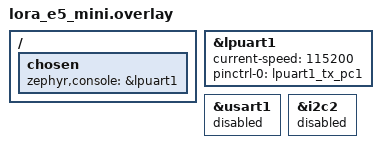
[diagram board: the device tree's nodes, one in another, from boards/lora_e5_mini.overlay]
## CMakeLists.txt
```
cmake_minimum_required(VERSION 3.20.0)
find_package(Zephyr REQUIRED HINTS $ENV{ZEPHYR_BASE})
project(loralink)

target_sources(app PRIVATE 
    src/main.c
    src/ping.c
    src/pong.c
)

if(DEFINED FW_VERSION)
    add_compile_definitions(FW_VERSION="${FW_VERSION}")
endif()
```

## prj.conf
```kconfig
# LoRa driver subsystem
CONFIG_LORA=y
CONFIG_LORA_MODULE_BACKEND_NATIVE=y

CONFIG_GPIO=y

# Main app
CONFIG_MAIN_STACK_SIZE=2048

# Power management
CONFIG_PM=y
CONFIG_PM_DEVICE=y

# Logging / shell management
CONFIG_LOG=y
CONFIG_SHELL=n
CONFIG_CONSOLE=y
CONFIG_DEBUG=n
```

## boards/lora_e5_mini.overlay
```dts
&lpuart1 {
	status = "okay";
	current-speed = <115200>;
	// pinctrl-0 = <&lpuart1_tx_pc1 &lpuart1_rx_pc0>;
	pinctrl-0 = <&lpuart1_tx_pc1>;
	pinctrl-names = "default";
};

/ {
	chosen {
		zephyr,console = &lpuart1;
	};
};

&usart1 {
	status = "disabled";
};

&i2c2 {
	status = "disabled";
};
```

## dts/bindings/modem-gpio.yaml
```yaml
# Copyright (c) 2023 Libre Solar Technologies GmbH
# SPDX-License-Identifier: Apache-2.0

description: GPIO pin to control GPIO interface on cellular modem.

compatible: "modem-gpio"

properties:
  gpios:
    type: phandle-array
    required: true
    description: |
      The GPIO pin to control DE/nRE on an RS485 transciever.
```

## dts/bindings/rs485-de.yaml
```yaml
# Copyright (c) 2023 Libre Solar Technologies GmbH
# SPDX-License-Identifier: Apache-2.0

description: GPIO pin to control DE/nRE on an RS485 transciever.

compatible: "rs485-de"

properties:
  gpios:
    type: phandle-array
    required: true
    description: |
      The GPIO pin to control DE/nRE on an RS485 transciever.
```

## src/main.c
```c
#ifdef ROLE_PING
#include "ping.h"
#define main_fcn main_ping
#endif

#ifdef ROLE_PONG
#include "pong.h"
#define main_fcn main_pong
#endif
// #include <zephyr/sleep.h>
int main(void)
{
	main_fcn();
	// while (1) {
	// 	k_msleep(1000);
	// }
}
```

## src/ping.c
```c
/*
 * Board A ("pinger"): sends a PING every 5 s, listens briefly for a PONG,
 * then lets the SoC drop into Stop2 for the rest of the period. No
 * app-level PM calls are needed -- with CONFIG_PM=y the idle thread picks
 * the deepest residency-appropriate power state automatically whenever
 * nothing is runnable (i.e. during k_sleep()).
 */
#include "ping.h"

LOG_MODULE_REGISTER(pinger, LOG_LEVEL_INF);

static const struct device *lora_dev = DEVICE_DT_GET(DT_ALIAS(lora0));

static int configure_for_tx(uint16_t preamble_symbols)
{
	struct lora_modem_config cfg = {
		.frequency = LORA_FREQUENCY_HZ,
		.bandwidth = LORA_BANDWIDTH,
		.datarate = LORA_SPREADING_FACT,
		.coding_rate = LORA_CODING_RATE,
		.preamble_len = preamble_symbols,
		.tx_power = LORA_TX_POWER_DBM,
		.tx = true,
	};

	return lora_config(lora_dev, &cfg);
}

static int configure_for_rx(void)
{
	struct lora_modem_config cfg = {
		.frequency = LORA_FREQUENCY_HZ,
		.bandwidth = LORA_BANDWIDTH,
		.datarate = LORA_SPREADING_FACT,
		.coding_rate = LORA_CODING_RATE,
		.preamble_len = DEFAULT_PREAMBLE_SYMBOLS,
		.tx_power = LORA_TX_POWER_DBM,
		.tx = false,
	};

	return lora_config(lora_dev, &cfg);
}

int main_ping(void)
{
	uint32_t seq = 0;

	if (!device_is_ready(lora_dev)) {
		LOG_ERR("LoRa device not ready");
		return -ENODEV;
	}

	while (1) {
		struct ping_pong_pkt tx_pkt = {
			.magic = PKT_MAGIC,
			.type = PKT_PING,
			.seq = seq++,
		};
		int ret;

		/*
		 * Long preamble so Board B's hardware RX duty cycle
		 * (rx=50 ms / sleep=450 ms) is guaranteed to catch it
		 * during one of its listen windows. See proto.h.
		 */
		ret = configure_for_tx(PING_PREAMBLE_SYMBOLS);
		if (ret < 0) {
			LOG_ERR("lora_config (tx) failed: %d", ret);
			goto sleep;
		}

		LOG_INF("Sending PING seq=%u", tx_pkt.seq);
		ret = lora_send(lora_dev, (uint8_t *)&tx_pkt, sizeof(tx_pkt));
		if (ret < 0) {
			LOG_ERR("lora_send failed: %d", ret);
			goto sleep;
		}

		/* Switch to RX and listen briefly for Board B's reply. */
		ret = configure_for_rx();
		if (ret < 0) {
			LOG_ERR("lora_config (rx) failed: %d", ret);
			goto sleep;
		}

		uint8_t rx_buf[32];
		int16_t rssi;
		int8_t snr;

		ret = lora_recv(lora_dev, rx_buf, sizeof(rx_buf), K_MSEC(PONG_LISTEN_MS), &rssi,
				&snr);
		if (ret > 0) {
			struct ping_pong_pkt *rx_pkt = (struct ping_pong_pkt *)rx_buf;

			if (ret >= (int)sizeof(*rx_pkt) && rx_pkt->magic == PKT_MAGIC &&
			    rx_pkt->type == PKT_PONG) {
				LOG_INF("Got PONG seq=%u rssi=%d snr=%d", rx_pkt->seq, rssi, snr);
			} else {
				LOG_WRN("Ignoring unrecognized %d-byte reply", ret);
			}
		} else if (ret == -EAGAIN || ret == 0) {
			LOG_WRN("No PONG received (timeout)");
		} else {
			LOG_ERR("lora_recv error: %d", ret);
		}

sleep:
		/*
		 * k_sleep() lets the idle thread pick Stop0/1/2 depending on
		 * residency. This is where nearly all of the power saving
		 * for Board A comes from.
		 */
		k_sleep(K_SECONDS(PING_PERIOD_S));
	}

	return 0;
}
```

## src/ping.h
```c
#ifndef PING_H

#include <zephyr/kernel.h>
#include <zephyr/device.h>
#include <zephyr/drivers/lora.h>
#include <zephyr/logging/log.h>
#include "proto.h"

int main_ping(void);
static int configure_for_rx(void);
static int configure_for_tx(uint16_t preamble_symbols);

#endif
```

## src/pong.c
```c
/*
 * Board B ("ponger"): the radio autonomously duty-cycles between a short
 * RX window and sleep (lora_recv_duty_cycle()). The calling thread blocks
 * the whole time; the SoC can drop into Stop2 and only comes back when the
 * radio's own IRQ fires on a detected packet -- that's the actual
 * "deep sleep except when woken by received data" behavior.
 *
 * NOTE: lora_recv_duty_cycle()/_async() are a fairly recent addition to
 * zephyr/drivers/lora.h. If your Zephyr checkout predates it, this file
 * won't build -- fall back to the plain lora_recv(..., K_FOREVER, ...)
 * version described in README.md (continuous RX; still lets the CPU
 * sleep, but the radio itself burns full RX current the whole time
 * instead of duty-cycling).
 */

#include "pong.h"

LOG_MODULE_REGISTER(ponger, LOG_LEVEL_INF);

static const struct device *lora_dev = DEVICE_DT_GET(DT_ALIAS(lora0));

static int configure_for_rx(void)
{
	struct lora_modem_config cfg = {
		.frequency = LORA_FREQUENCY_HZ,
		.bandwidth = LORA_BANDWIDTH,
		.datarate = LORA_SPREADING_FACT,
		.coding_rate = LORA_CODING_RATE,
		.preamble_len = DEFAULT_PREAMBLE_SYMBOLS,
		.tx_power = LORA_TX_POWER_DBM,
		.tx = false,
	};

	return lora_config(lora_dev, &cfg);
}

static int configure_for_tx(void)
{
	struct lora_modem_config cfg = {
		.frequency = LORA_FREQUENCY_HZ,
		.bandwidth = LORA_BANDWIDTH,
		.datarate = LORA_SPREADING_FACT,
		.coding_rate = LORA_CODING_RATE,
		.preamble_len = DEFAULT_PREAMBLE_SYMBOLS,
		.tx_power = LORA_TX_POWER_DBM,
		.tx = true,
	};

	return lora_config(lora_dev, &cfg);
}

int main_pong(void)
{
	int ret;

	if (!device_is_ready(lora_dev)) {
		LOG_ERR("LoRa device not ready");
		return -ENODEV;
	}

	ret = configure_for_rx();
	if (ret < 0) {
		LOG_ERR("lora_config (rx) failed: %d", ret);
		return ret;
	}

	LOG_INF("Ponger ready: duty-cycled RX (rx=%dms sleep=%dms)", DUTY_RX_WINDOW_MS,
		DUTY_SLEEP_WINDOW_MS);

	while (1) {
		uint8_t rx_buf[32];
		int16_t rssi;
		int8_t snr;

		ret = lora_recv_duty_cycle(lora_dev, K_MSEC(DUTY_RX_WINDOW_MS),
					   K_MSEC(DUTY_SLEEP_WINDOW_MS), rx_buf, sizeof(rx_buf),
					   K_FOREVER, &rssi, &snr);
		if (ret <= 0) {
			LOG_WRN("lora_recv_duty_cycle error: %d", ret);
			configure_for_rx();
			continue;
		}

		struct ping_pong_pkt *rx_pkt = (struct ping_pong_pkt *)rx_buf;

		if (ret < (int)sizeof(*rx_pkt) || rx_pkt->magic != PKT_MAGIC ||
		    rx_pkt->type != PKT_PING) {
			LOG_WRN("Ignoring unrecognized %d-byte packet", ret);
			configure_for_rx();
			continue;
		}

		LOG_INF("Got PING seq=%u rssi=%d snr=%d", rx_pkt->seq, rssi, snr);

		struct ping_pong_pkt tx_pkt = {
			.magic = PKT_MAGIC,
			.type = PKT_PONG,
			.seq = rx_pkt->seq,
		};

		ret = configure_for_tx();
		if (ret < 0) {
			LOG_ERR("lora_config (tx) failed: %d", ret);
			continue;
		}

		ret = lora_send(lora_dev, (uint8_t *)&tx_pkt, sizeof(tx_pkt));
		if (ret < 0) {
			LOG_ERR("lora_send (pong) failed: %d", ret);
		}

		/* Back to duty-cycled RX for the next ping. */
		configure_for_rx();
	}

	return 0;
}
```

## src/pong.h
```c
#ifndef PONG_H

#include <zephyr/kernel.h>
#include <zephyr/device.h>
#include <zephyr/drivers/lora.h>
#include <zephyr/logging/log.h>

#include "proto.h"

int main_pong(void);
static int configure_for_tx(void);
static int configure_for_rx(void);

#endif
```

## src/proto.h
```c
#ifndef APP_PROTO_H
#define APP_PROTO_H

#include <stdint.h>

/*
 * Radio parameters shared by both boards. Both ends MUST agree on
 * frequency/bandwidth/SF/CR or they won't hear each other.
 *
 * 868.1 MHz / SF7 / 125 kHz / CR 4:5 is a common EU868 "LoRaWAN-like"
 * single-channel config. Swap to 915 MHz (e.g. 915000000) and check your
 * local ISM-band rules if you're in a US915 region -- the LoRa-E5 module
 * is sold in HF (863-928 MHz) and LF (410-493 MHz) variants, so make sure
 * this frequency is actually inside the band your module covers.
 */
#define LORA_FREQUENCY_HZ   868100000
#define LORA_BANDWIDTH      BW_125_KHZ
#define LORA_SPREADING_FACT SF_7
#define LORA_CODING_RATE    CR_4_5
#define LORA_TX_POWER_DBM   14

/*
 * Board A's ping preamble must be long enough to guarantee Board B's
 * duty-cycled receiver is awake and listening somewhere during it:
 *
 *   preamble_symbols > (rx_period_ms + sleep_period_ms) / symbol_time_ms
 *
 * symbol_time_ms = (2^SF / BW_hz) * 1000. For SF7/125kHz that's ~1.024 ms.
 * With rx=50ms / sleep=450ms (500ms duty cycle period) that needs a
 * preamble of >489 symbols. Recompute this if you change SF/BW/duty
 * cycle periods -- see README.md.
 */
#define PING_PREAMBLE_SYMBOLS  600
#define DEFAULT_PREAMBLE_SYMBOLS 8   /* used for the PONG reply */

#define PING_PERIOD_S        5
#define PONG_LISTEN_MS        2000  /* how long A listens for a PONG */

/* Board B's hardware RX duty cycle (radio-autonomous, not CPU-driven) */
#define DUTY_RX_WINDOW_MS      50
#define DUTY_SLEEP_WINDOW_MS  450

#define PKT_MAGIC 0x50 /* 'P' */

enum pkt_type {
	PKT_PING = 1,
	PKT_PONG = 2,
};

struct __packed ping_pong_pkt {
	uint8_t magic;
	uint8_t type;
	uint32_t seq;
};

#endif /* APP_PROTO_H */
```
